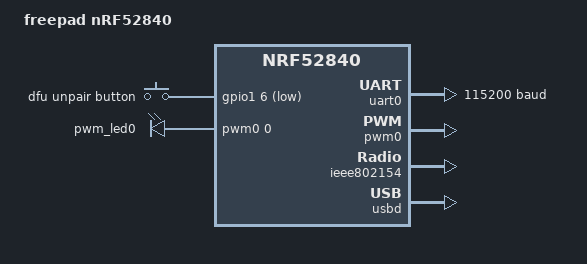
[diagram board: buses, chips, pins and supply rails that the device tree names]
/*
 * Copyright (c) 2022 Nikola Trifunovic
 * Copyright (c) 2018 Nordic Semiconductor ASA
 * Copyright (c) 2017 Linaro Limited
 *
 * SPDX-License-Identifier: Apache-2.0
 */

/dts-v1/;
#include <nordic/nrf52840_qiaa.dtsi>
#include "freepad_nrf52840-pinctrl.dtsi"

/ {
	model = "freepad nRF52840";
	compatible = "freepad_nrf52840";

	chosen {
		zephyr,console = &uart0;
		zephyr,shell-uart = &uart0;
		zephyr,uart-mcumgr = &uart0;
		zephyr,bt-mon-uart = &uart0;
		zephyr,bt-c2h-uart = &uart0;
		zephyr,sram = &sram0;
		zephyr,flash = &flash0;
		zephyr,code-partition = &slot0_partition;
		zephyr,ieee802154 = &ieee802154;
	};

	buttons {
		compatible = "gpio-keys";
		func_button {
			gpios = <&gpio1 6 (GPIO_PULL_UP | GPIO_ACTIVE_LOW)>;
			label = "dfu unpair button";
		};
	};

	pwmleds {
		compatible = "pwm-leds";
		pwm_led0: pwm_led_0 {
			pwms = <&pwm0 0 PWM_MSEC(20) PWM_POLARITY_INVERTED>;
		};
	};

	/* These aliases are provided for compatibility with samples */
	aliases {
		watchdog0 = &wdt0;
		pwm-led0 = &pwm_led0;
	};
};

&gpiote {
	status = "okay";
};

&gpio0 {
	status = "okay";
};

&gpio1 {
	status = "okay";
};

&uart0 {
	compatible = "nordic,nrf-uarte";
	status = "okay";
	current-speed = <115200>;
	pinctrl-0 = <&uart0_default>;
	pinctrl-1 = <&uart0_sleep>;
	pinctrl-names = "default", "sleep";
};

&pwm0 {
	status = "okay";
	pinctrl-0 = <&pwm0_default>;
	pinctrl-1 = <&pwm0_sleep>;
	pinctrl-names = "default", "sleep";
};

&ieee802154 {
	status = "okay";
};

/* Include flash partition table.
 * Two partition tables are available:
 * fstab-stock		-compatible with Nordic nRF5 bootloader, default
 * fstab-debugger	-to use an external debugger, w/o the nRF5 bootloader
 */
#include "fstab-stock.dts"

zephyr_udc0: &usbd {
	compatible = "nordic,nrf-usbd";
	status = "okay";
};
